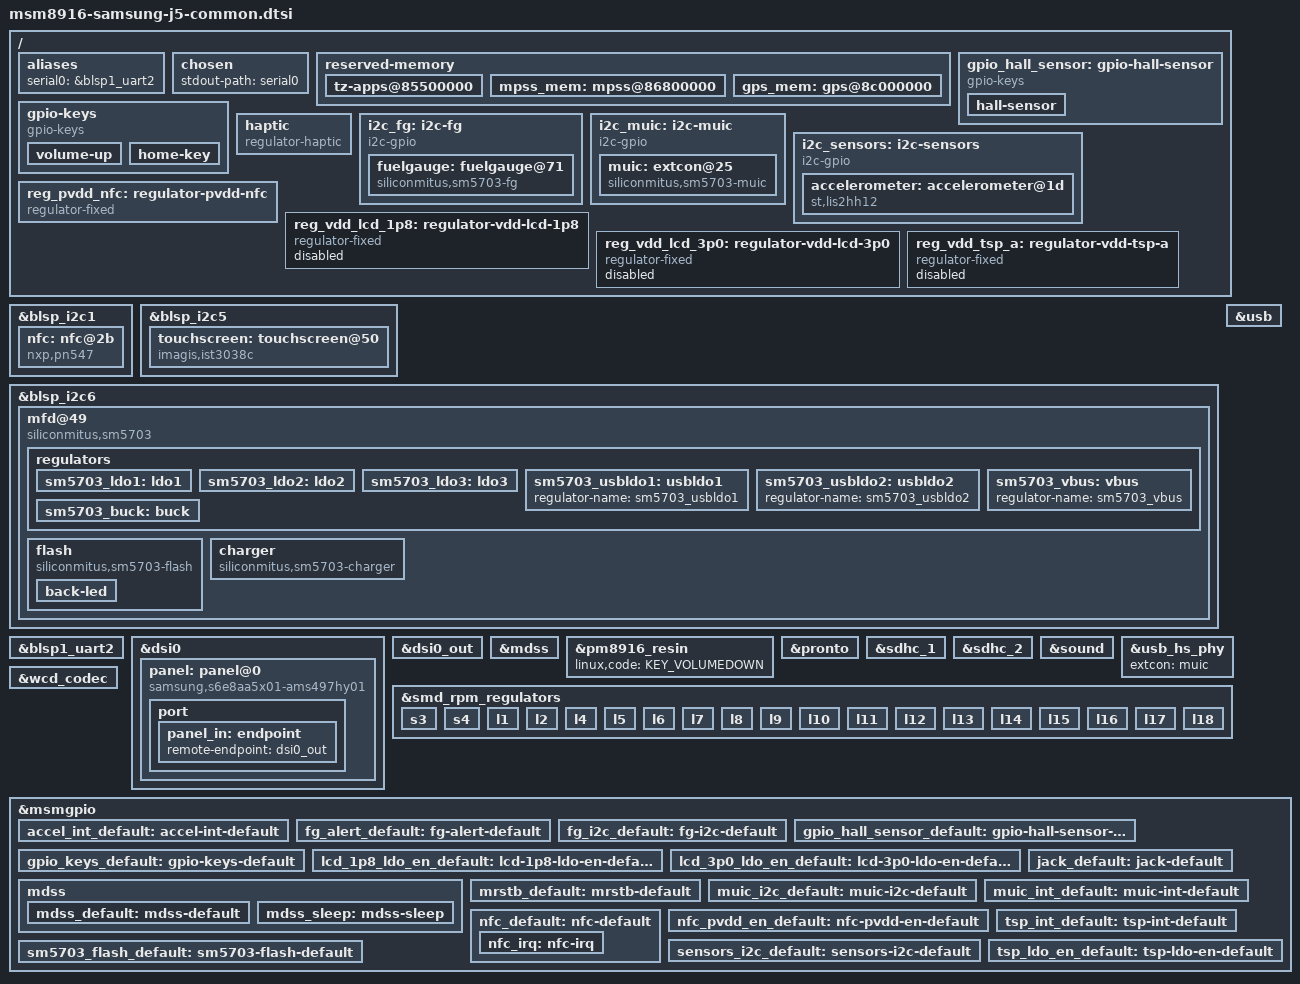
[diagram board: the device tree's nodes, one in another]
// SPDX-License-Identifier: GPL-2.0-only

#include "msm8916-pm8916.dtsi"
#include "msm8916-modem.dtsi"

#include <dt-bindings/gpio/gpio.h>
#include <dt-bindings/input/input.h>
#include <dt-bindings/interrupt-controller/irq.h>
#include <dt-bindings/leds/common.h>

/ {
	aliases {
		serial0 = &blsp1_uart2;
	};

	chosen {
		stdout-path = "serial0";
	};

	reserved-memory {
		/* Additional memory used by Samsung firmware modifications */
		tz-apps@85500000 {
			reg = <0x0 0x85500000 0x0 0xb00000>;
			no-map;
		};

		mpss_mem: mpss@86800000 {
			reg = <0x0 0x86800000 0x0 0x5800000>;
			no-map;
		};

		gps_mem: gps@8c000000 {
			reg = <0x0 0x8c000000 0x0 0x200000>;
			no-map;
		};
	};

	gpio_hall_sensor: gpio-hall-sensor {
		compatible = "gpio-keys";

		pinctrl-names = "default";
		pinctrl-0 = <&gpio_hall_sensor_default>;

		label = "GPIO Hall Effect Sensor";

		hall-sensor {
			label = "Hall Effect Sensor";
			gpios = <&msmgpio 52 GPIO_ACTIVE_LOW>;
			linux,input-type = <EV_SW>;
			linux,code = <SW_LID>;
			linux,can-disable;
		};
	};

	gpio-keys {
		compatible = "gpio-keys";

		pinctrl-names = "default";
		pinctrl-0 = <&gpio_keys_default>;

		label = "GPIO Buttons";

		volume-up {
			label = "Volume Up";
			gpios = <&msmgpio 107 GPIO_ACTIVE_LOW>;
			linux,code = <KEY_VOLUMEUP>;
		};

		home-key {
			label = "Home Key";
			gpios = <&msmgpio 109 GPIO_ACTIVE_LOW>;
			linux,code = <KEY_HOMEPAGE>;
		};
	};

	haptic {
		compatible = "regulator-haptic";
		haptic-supply = <&sm5703_ldo2>;
		min-microvolt = <3300000>;
		max-microvolt = <3300000>;
	};

	i2c_fg: i2c-fg {
		compatible = "i2c-gpio";

		sda-gpios = <&msmgpio 14 (GPIO_ACTIVE_HIGH|GPIO_OPEN_DRAIN)>;
		scl-gpios = <&msmgpio 15 (GPIO_ACTIVE_HIGH|GPIO_OPEN_DRAIN)>;

		pinctrl-names = "default";
		pinctrl-0 = <&fg_i2c_default>;
		status = "okay";

		#address-cells = <1>;
		#size-cells = <0>;

		fuelgauge: fuelgauge@71 {
			compatible = "siliconmitus,sm5703-fg";
			reg = <0x71>;

			interrupt-parent = <&msmgpio>;
			interrupts = <121 IRQ_TYPE_EDGE_FALLING>;

			pinctrl-names = "default";
			pinctrl-0 = <&fg_alert_default>;
		};
	};

	i2c_muic: i2c-muic {
		compatible = "i2c-gpio";
		sda-gpios = <&msmgpio 105 (GPIO_ACTIVE_HIGH|GPIO_OPEN_DRAIN)>;
		scl-gpios = <&msmgpio 106 (GPIO_ACTIVE_HIGH|GPIO_OPEN_DRAIN)>;

		pinctrl-names = "default";
		pinctrl-0 = <&muic_i2c_default>;

		#address-cells = <1>;
		#size-cells = <0>;

		muic: extcon@25 {
			compatible = "siliconmitus,sm5703-muic";
			reg = <0x25>;

			interrupt-parent = <&msmgpio>;
			interrupts = <12 IRQ_TYPE_EDGE_FALLING>;

			pinctrl-names = "default";
			pinctrl-0 = <&muic_int_default>;
		};
	};

	i2c_sensors: i2c-sensors {
		compatible = "i2c-gpio";

		sda-gpios = <&msmgpio 31 (GPIO_ACTIVE_HIGH|GPIO_OPEN_DRAIN)>;
		scl-gpios = <&msmgpio 32 (GPIO_ACTIVE_HIGH|GPIO_OPEN_DRAIN)>;

		pinctrl-names = "default";
		pinctrl-0 = <&sensors_i2c_default>;

		#address-cells = <1>;
		#size-cells = <0>;

		accelerometer: accelerometer@1d {
			compatible = "st,lis2hh12";
			reg = <0x1d>;

			interrupt-parent = <&msmgpio>;
			interrupts = <115 IRQ_TYPE_LEVEL_HIGH>;
			interrupt-names = "INT1";

			pinctrl-names = "default";
			pinctrl-0 = <&accel_int_default>;

			st,drdy-int-pin = <1>;
		};
	};

	reg_pvdd_nfc: regulator-pvdd-nfc {
		compatible = "regulator-fixed";
		regulator-name = "pvdd_nfc";
		regulator-min-microvolt = <1800000>;
		regulator-max-microvolt = <1800000>;

		enable-active-high;

		pinctrl-names = "default";
		pinctrl-0 = <&nfc_pvdd_en_default>;
	};

	reg_vdd_lcd_1p8: regulator-vdd-lcd-1p8 {
		compatible = "regulator-fixed";
		regulator-name = "vdd_lcd_1p8";
		regulator-min-microvolt = <1800000>;
		regulator-max-microvolt = <1800000>;
		vin-supply = <&pm8916_s4>;

		enable-active-high;

		pinctrl-names = "default";
		pinctrl-0 = <&lcd_1p8_ldo_en_default>;

		status = "disabled";
	};

	reg_vdd_lcd_3p0: regulator-vdd-lcd-3p0 {
		compatible = "regulator-fixed";
		regulator-name = "vdd_lcd_3p0";
		regulator-min-microvolt = <3000000>;
		regulator-max-microvolt = <3000000>;

		enable-active-high;

		pinctrl-names = "default";
		pinctrl-0 = <&lcd_3p0_ldo_en_default>;

		status = "disabled";
	};

	reg_vdd_tsp_a: regulator-vdd-tsp-a {
		compatible = "regulator-fixed";
		regulator-name = "vdd_tsp_a";
		regulator-min-microvolt = <3000000>;
		regulator-max-microvolt = <3000000>;

		enable-active-high;

		pinctrl-names = "default";
		pinctrl-0 = <&tsp_ldo_en_default>;

		status = "disabled";
	};
};

&blsp_i2c1 {
	status = "okay";

	nfc: nfc@2b {
		compatible = "nxp,pn547", "nxp,nxp-nci-i2c";
		reg = <0x2b>;

		interrupt-parent = <&msmgpio>;
		interrupts = <21 IRQ_TYPE_EDGE_RISING>;

		enable-gpios = <&msmgpio 20 GPIO_ACTIVE_HIGH>;
		firmware-gpios = <&msmgpio 49 GPIO_ACTIVE_HIGH>;

		pinctrl-names = "default";
		pinctrl-0 = <&nfc_default>;

		pvdd-supply = <&reg_pvdd_nfc>;
	};
};

&blsp_i2c5 {
	status = "okay";

	touchscreen: touchscreen@50 {
		compatible = "imagis,ist3038c";
		reg = <0x50>;

		interrupt-parent = <&msmgpio>;
		interrupts = <13 IRQ_TYPE_EDGE_FALLING>;

		touchscreen-size-x = <720>;
		touchscreen-size-y = <1280>;

		vdd-supply = <&reg_vdd_tsp_a>;
		vddio-supply = <&pm8916_l6>;

		pinctrl-names = "default";
		pinctrl-0 = <&tsp_int_default>;
	};
};

&blsp_i2c6 {
	status = "okay";

	mfd@49 {
		compatible = "siliconmitus,sm5703";
		reg = <0x49>;

		reset-gpio = <&msmgpio 24 GPIO_ACTIVE_HIGH>;

		pinctrl-names = "default";
		pinctrl-0 = <&mrstb_default>;

		regulators {
			sm5703_ldo1: ldo1 {
				regulator-name = "sm5703_ldo1";
				regulator-min-microvolt = <2800000>;
				regulator-max-microvolt = <2800000>;
			};

			sm5703_ldo2: ldo2 {
				regulator-name = "sm5703_ldo2";
				regulator-min-microvolt = <1500000>;
				regulator-max-microvolt = <3300000>;
			};

			sm5703_ldo3: ldo3 {
				regulator-name = "sm5703_ldo3";
				regulator-min-microvolt = <3300000>;
				regulator-max-microvolt = <3300000>;
			};

			sm5703_usbldo1: usbldo1 {
				regulator-name = "sm5703_usbldo1";
			};

			sm5703_usbldo2: usbldo2 {
				regulator-name = "sm5703_usbldo2";
			};

			sm5703_vbus: vbus {
				regulator-name = "sm5703_vbus";
			};

			sm5703_buck: buck {
				regulator-name = "sm5703_buck";
				regulator-min-microvolt = <1500000>;
				regulator-max-microvolt = <1500000>;
			};
		};

		flash {
			compatible = "siliconmitus,sm5703-flash";

			flash-gpio = <&msmgpio 34 GPIO_ACTIVE_HIGH>;
			torch-gpio = <&msmgpio 36 GPIO_ACTIVE_HIGH>;

			pinctrl-names = "default";
			pinctrl-0 = <&sm5703_flash_default>;

			back-led {
				function = LED_FUNCTION_FLASH;
				color = <LED_COLOR_ID_WHITE>;
				led-max-microamp = <170000>;
				flash-max-microamp = <1200000>;
			};
		};

		charger {
			compatible = "siliconmitus,sm5703-charger";
			siliconmitus,enable-autoset;
			siliconmitus,enable-autostop;
		};
	};
};

&blsp1_uart2 {
	status = "okay";
};

&dsi0 {
	pinctrl-names = "default", "sleep";
	pinctrl-0 = <&mdss_default>;
	pinctrl-1 = <&mdss_sleep>;

	panel: panel@0 {
		reg = <0>;

		compatible = "samsung,s6e8aa5x01-ams497hy01";

		reset-gpios = <&msmgpio 25 GPIO_ACTIVE_LOW>;

		port {
			panel_in: endpoint {
				remote-endpoint = <&dsi0_out>;
			};
		};
	};
};

&dsi0_out {
	data-lanes = <0 1 2 3>;
	remote-endpoint = <&panel_in>;
};

&mdss {
	status = "okay";
};

&pm8916_resin {
	status = "okay";
	linux,code = <KEY_VOLUMEDOWN>;
};

&pronto {
	status = "okay";
};

&sdhc_1 {
	status = "okay";

	pinctrl-names = "default", "sleep";
	pinctrl-0 = <&sdc1_clk_on &sdc1_cmd_on &sdc1_data_on>;
	pinctrl-1 = <&sdc1_clk_off &sdc1_cmd_off &sdc1_data_off>;
};

&sdhc_2 {
	status = "okay";

	pinctrl-names = "default", "sleep";
	pinctrl-0 = <&sdc2_clk_on &sdc2_cmd_on &sdc2_data_on &sdc2_cd_on>;
	pinctrl-1 = <&sdc2_clk_off &sdc2_cmd_off &sdc2_data_off &sdc2_cd_off>;

	cd-gpios = <&msmgpio 38 GPIO_ACTIVE_LOW>;
};

&sound {
	status = "okay";
	audio-routing =
		"AMIC1", "MIC BIAS External1",
		"AMIC2", "MIC BIAS Internal2",
		"AMIC3", "MIC BIAS External1";
};

&usb {
	status = "okay";
	extcon = <&muic>, <&muic>;
	vbus-supply = <&sm5703_vbus>;
};

&usb_hs_phy {
	extcon = <&muic>;
};

&wcd_codec {
	jack-gpios = <&msmgpio 110 GPIO_ACTIVE_LOW>;
	qcom,micbias-lvl = <2800>;
	qcom,mbhc-vthreshold-low = <75 150 237 450 500>;
	qcom,mbhc-vthreshold-high = <75 150 237 450 500>;

	pinctrl-names = "default";
	pinctrl-0 = <&jack_default>;
};

&smd_rpm_regulators {
	vdd_l1_l2_l3-supply = <&pm8916_s3>;
	vdd_l4_l5_l6-supply = <&pm8916_s4>;
	vdd_l7-supply = <&pm8916_s4>;

	s3 {
		regulator-min-microvolt = <1200000>;
		regulator-max-microvolt = <1300000>;
	};

	s4 {
		regulator-min-microvolt = <1800000>;
		regulator-max-microvolt = <2100000>;
	};

	l1 {
		regulator-min-microvolt = <1225000>;
		regulator-max-microvolt = <1225000>;
	};

	l2 {
		regulator-min-microvolt = <1200000>;
		regulator-max-microvolt = <1200000>;
	};

	l4 {
		regulator-min-microvolt = <2050000>;
		regulator-max-microvolt = <2050000>;
	};

	l5 {
		regulator-min-microvolt = <1800000>;
		regulator-max-microvolt = <1800000>;
	};

	l6 {
		regulator-min-microvolt = <1800000>;
		regulator-max-microvolt = <1800000>;
	};

	l7 {
		regulator-min-microvolt = <1800000>;
		regulator-max-microvolt = <1800000>;
	};

	l8 {
		regulator-min-microvolt = <2850000>;
		regulator-max-microvolt = <2900000>;
	};

	l9 {
		regulator-min-microvolt = <3300000>;
		regulator-max-microvolt = <3300000>;
	};

	l10 {
		regulator-min-microvolt = <2700000>;
		regulator-max-microvolt = <2800000>;
	};

	l11 {
		regulator-min-microvolt = <1800000>;
		regulator-max-microvolt = <2950000>;
		regulator-allow-set-load;
		regulator-system-load = <200000>;
	};

	l12 {
		regulator-min-microvolt = <1800000>;
		regulator-max-microvolt = <2950000>;
	};

	l13 {
		regulator-min-microvolt = <3075000>;
		regulator-max-microvolt = <3075000>;
	};

	l14 {
		regulator-min-microvolt = <1800000>;
		regulator-max-microvolt = <3300000>;
	};

	l15 {
		regulator-min-microvolt = <1800000>;
		regulator-max-microvolt = <3300000>;
	};

	l16 {
		regulator-min-microvolt = <1800000>;
		regulator-max-microvolt = <3300000>;
	};

	l17 {
		regulator-min-microvolt = <3000000>;
		regulator-max-microvolt = <3000000>;
	};

	l18 {
		regulator-min-microvolt = <2700000>;
		regulator-max-microvolt = <2700000>;
	};
};

&msmgpio {
	accel_int_default: accel-int-default {
		pins = "gpio115";
		function = "gpio";

		drive-strength = <2>;
		bias-disable;
	};

	fg_alert_default: fg-alert-default {
		pins = "gpio121";
		function = "gpio";

		drive-strength = <2>;
		bias-disable;
	};

	fg_i2c_default: fg-i2c-default {
		pins = "gpio14", "gpio15";
		function = "gpio";

		drive-strength = <2>;
		bias-disable;
	};

	gpio_hall_sensor_default: gpio-hall-sensor-default {
		pins = "gpio52";
		function = "gpio";

		drive-strength = <2>;
		bias-disable;
	};

	gpio_keys_default: gpio-keys-default {
		pins = "gpio107", "gpio109";
		function = "gpio";

		drive-strength = <2>;
		bias-pull-up;
	};

	lcd_1p8_ldo_en_default: lcd-1p8-ldo-en-default {
		function = "gpio";

		drive-strength = <2>;
		bias-disable;
	};

	lcd_3p0_ldo_en_default: lcd-3p0-ldo-en-default {
		function = "gpio";

		drive-strength = <2>;
		bias-disable;
	};

	jack_default: jack-default {
		pins = "gpio110";
		function = "gpio";

		drive-strength = <2>;
		bias-disable;
	};

	mdss {
		mdss_default: mdss-default {
			pins = "gpio25";
			function = "gpio";

			drive-strength = <8>;
			bias-disable;
		};
		mdss_sleep: mdss-sleep {
			pins = "gpio25";
			function = "gpio";

			drive-strength = <2>;
			bias-pull-down;
		};
	};

	mrstb_default: mrstb-default {
		pins = "gpio24";
		function = "gpio";

		drive-strength = <2>;
		bias-disable;
	};

	muic_i2c_default: muic-i2c-default {
		pins = "gpio105", "gpio106";
		function = "gpio";

		drive-strength = <2>;
		bias-disable;
	};

	muic_int_default: muic-int-default {
		pins = "gpio12";
		function = "gpio";

		drive-strength = <2>;
		bias-disable;
	};

	nfc_default: nfc-default {
		pins = "gpio20", "gpio49";
		function = "gpio";

		drive-strength = <2>;
		bias-disable;

		nfc_irq: nfc-irq {
			pins = "gpio21";
			function = "gpio";

			drive-strength = <2>;
			bias-pull-down;
		};
	};

	nfc_pvdd_en_default: nfc-pvdd-en-default {
		function = "gpio";

		drive-strength = <2>;
		bias-disable;
	};

	sensors_i2c_default: sensors-i2c-default {
		pins = "gpio31", "gpio32";
		function = "gpio";

		drive-strength = <2>;
		bias-disable;
	};

	sm5703_flash_default: sm5703-flash-default {
		pins = "gpio34", "gpio36";
		function = "gpio";

		drive-strength = <2>;
		bias-disable;
	};

	tsp_int_default: tsp-int-default {
		pins = "gpio13";
		function = "gpio";

		drive-strength = <2>;
		bias-disable;
	};

	tsp_ldo_en_default: tsp-ldo-en-default {
		function = "gpio";

		drive-strength = <2>;
		bias-disable;
	};
};
